VERSION ""

NS_ :

BS_:
BU_: canandcoder
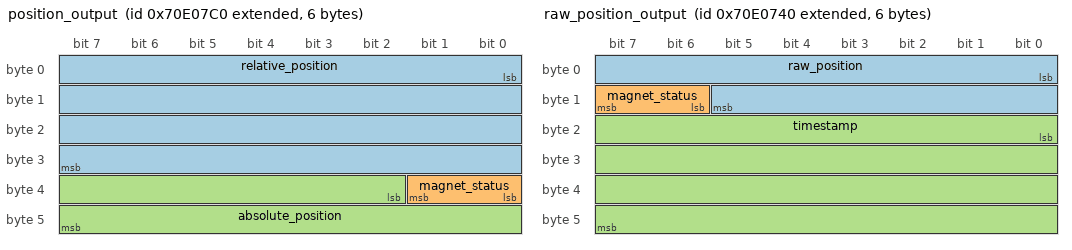
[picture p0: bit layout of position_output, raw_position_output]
BO_ 2265843648 position_output: 6 canandcoder
    SG_ relative_position : 0|32@1- (1,0) [-2147483648.0|2147483647.0] "" Vector__XXX
    SG_ magnet_status : 32|2@1+ (1,0) [0|3] "" Vector__XXX
    SG_ absolute_position : 34|14@1+ (1,0) [0|16383] "" Vector__XXX

BO_ 2265843584 velocity_output: 3 canandcoder
    SG_ velocity : 0|22@1- (1,0) [-2097152.0|2097151.0] "" Vector__XXX
    SG_ magnet_status : 22|2@1+ (1,0) [0|3] "" Vector__XXX

BO_ 2265843520 raw_position_output: 6 canandcoder
    SG_ raw_position : 0|14@1+ (1,0) [0|16383] "" Vector__XXX
    SG_ magnet_status : 14|2@1+ (1,0) [0|3] "" Vector__XXX
    SG_ timestamp : 16|32@1+ (1,0) [0|4294967295] "" Vector__XXX

BO_ 2265842112 party_mode: 1 Vector__XXX
    SG_ party_level : 0|8@1+ (1,0) [0|255] "" canandcoder

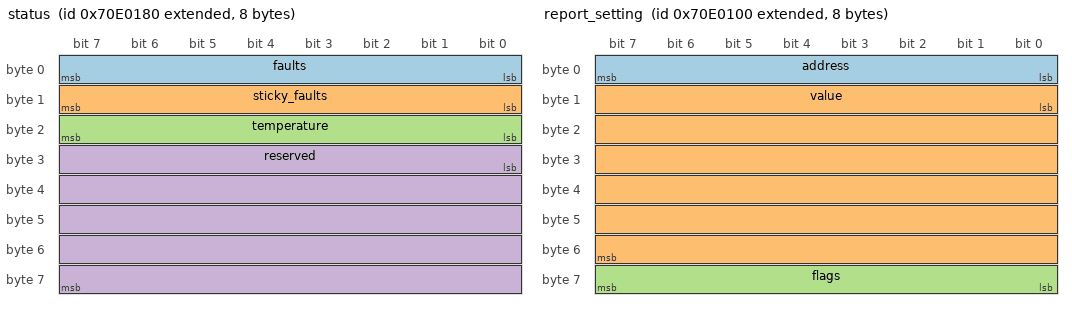
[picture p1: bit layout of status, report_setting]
BO_ 2265842048 status: 8 canandcoder
    SG_ faults : 0|8@1+ (1,0) [0|255] "" Vector__XXX
    SG_ sticky_faults : 8|8@1+ (1,0) [0|255] "" Vector__XXX
    SG_ temperature : 16|8@1- (1,0) [-128.0|127.0] "" Vector__XXX
    SG_ reserved : 24|40@1+ (1,0) [0|1099511627775] "" Vector__XXX

BO_ 2265841984 clear_sticky_faults: 1 Vector__XXX
    SG_ unused : 0|8@1+ (1,0) [0|255] "" canandcoder

BO_ 2265841920 report_setting: 8 canandcoder
    SG_ address : 0|8@1+ (1,0) [0|255] "" Vector__XXX
    SG_ value : 8|48@1+ (1,0) [0|281474976710655] "" Vector__XXX
    SG_ flags : 56|8@1+ (1,0) [0|255] "" Vector__XXX

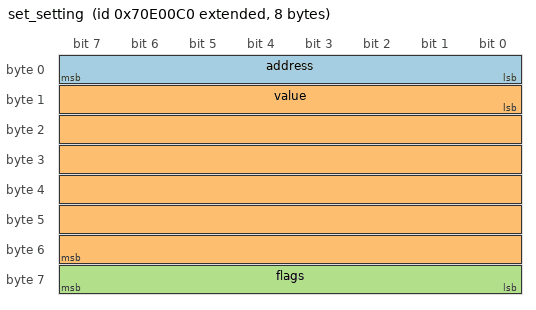
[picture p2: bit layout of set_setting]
BO_ 2265841856 set_setting: 8 Vector__XXX
    SG_ address : 0|8@1+ (1,0) [0|255] "" canandcoder
    SG_ value : 8|48@1+ (1,0) [0|281474976710655] "" canandcoder
    SG_ flags : 56|8@1+ (1,0) [0|255] "" canandcoder

BO_ 2265841792 setting_command: 2 Vector__XXX
    SG_ control_flag : 0|8@1+ (1,0) [0|255] "" canandcoder
    SG_ data : 8|8@1+ (1,0) [0|255] "" canandcoder
